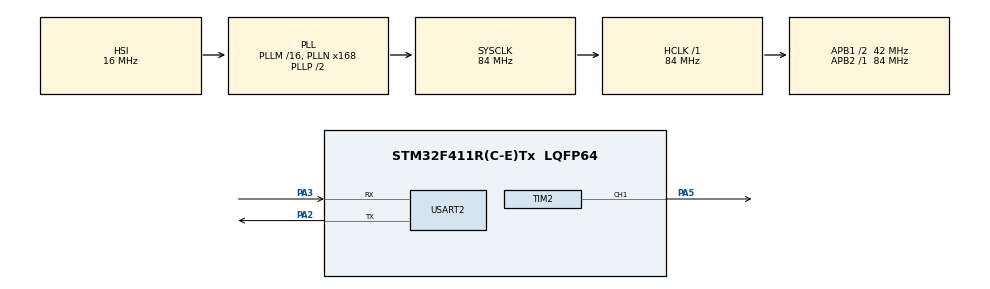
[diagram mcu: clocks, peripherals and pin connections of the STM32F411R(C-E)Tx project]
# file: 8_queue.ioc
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Dma.MEMTOMEM.0.Direction=DMA_MEMORY_TO_MEMORY
Dma.MEMTOMEM.0.FIFOMode=DMA_FIFOMODE_ENABLE
Dma.MEMTOMEM.0.FIFOThreshold=DMA_FIFO_THRESHOLD_FULL
Dma.MEMTOMEM.0.Instance=DMA2_Stream0
Dma.MEMTOMEM.0.MemBurst=DMA_MBURST_SINGLE
Dma.MEMTOMEM.0.MemDataAlignment=DMA_MDATAALIGN_BYTE
Dma.MEMTOMEM.0.MemInc=DMA_MINC_ENABLE
Dma.MEMTOMEM.0.Mode=DMA_NORMAL
Dma.MEMTOMEM.0.PeriphBurst=DMA_PBURST_SINGLE
Dma.MEMTOMEM.0.PeriphDataAlignment=DMA_PDATAALIGN_BYTE
Dma.MEMTOMEM.0.PeriphInc=DMA_PINC_ENABLE
Dma.MEMTOMEM.0.Priority=DMA_PRIORITY_LOW
Dma.Request0=MEMTOMEM
Mcu.Family=STM32F4
Mcu.Name=STM32F411R(C-E)Tx
Mcu.Package=LQFP64
NVIC.PriorityGroup=NVIC_PRIORITYGROUP_4
NVIC.TIM5_IRQn=true\:15\:0\:false\:false\:true\:false\:true\:true
NVIC.TimeBase=TIM5_IRQn
NVIC.TimeBaseIP=TIM5
NVIC.USART2_IRQn=true\:6\:0\:true\:false\:true\:true\:true\:true
PA13.Mode=Serial_Wire
PA13.Signal=SYS_JTMS-SWDIO
PA14.Mode=Serial_Wire
PA14.Signal=SYS_JTCK-SWCLK
PA2.Mode=Asynchronous
PA2.Signal=USART2_TX
PA3.Mode=Asynchronous
PA3.Signal=USART2_RX
PA5.Signal=S_TIM2_CH1_ETR
ProjectManager.HeapSize=0x200
ProjectManager.StackSize=0x400
ProjectManager.TargetToolchain=STM32CubeIDE
RCC.48MHZClocksFreq_Value=42000000
RCC.AHBFreq_Value=84000000
RCC.APB1CLKDivider=RCC_HCLK_DIV2
RCC.APB1Freq_Value=42000000
RCC.APB1TimFreq_Value=84000000
RCC.APB2Freq_Value=84000000
RCC.APB2TimFreq_Value=84000000
RCC.CortexFreq_Value=84000000
RCC.HCLKFreq_Value=84000000
RCC.HSE_VALUE=25000000
RCC.HSI_VALUE=16000000
RCC.LSE_VALUE=32768
RCC.PLLN=168
RCC.SYSCLKFreq_VALUE=84000000
RCC.SYSCLKSource=RCC_SYSCLKSOURCE_PLLCLK
RCC.VCOOutputFreq_Value=168000000
SH.S_TIM2_CH1_ETR.0=TIM2_CH1,PWM Generation1 CH1
TIM2.Channel-PWM\ Generation1\ CH1=TIM_CHANNEL_1
TIM2.Period=999
TIM2.Prescaler=83
TIM2.Pulse-PWM\ Generation1\ CH1=31250
USART2.VirtualMode=VM_ASYNC
VP_RTC_VS_RTC_Activate.Mode=RTC_Enabled
VP_SYS_VS_tim5.Mode=TIM5
VP_TIM2_VS_ClockSourceINT.Mode=Internal
board=custom

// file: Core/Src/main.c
/* USER CODE BEGIN Header */
/**
 ******************************************************************************
 * @file           : main.c
 * @brief          : Main program body
 ******************************************************************************
 * @attention
 *
 * Copyright (c) 2024 STMicroelectronics.
 * All rights reserved.
 *
 * This software is licensed under terms that can be found in the LICENSE file
 * in the root directory of this software component.
 * If no LICENSE file comes with this software, it is provided AS-IS.
 *
 ******************************************************************************
 */
/* USER CODE END Header */
#include "main.h"

/* USER CODE BEGIN PD */
xTaskHandle handle_cmd_task;
xTaskHandle handle_menu_task;
xTaskHandle handle_uart_task;
xTaskHandle handle_led_task;
xTaskHandle handle_rtc_task;
xTaskHandle handle_dma_task;

TimerHandle_t handle_led_timer;

QueueHandle_t q_data;
QueueHandle_t q_print;

volatile uint8_t user_data;

/* USER CODE END PD */

RTC_HandleTypeDef hrtc;

TIM_HandleTypeDef htim2;

UART_HandleTypeDef huart2;

DMA_HandleTypeDef hdma_memtomem_dma2_stream0;
/* USER CODE BEGIN PV */
char hello[18] = "Hello, Project 8.\n";
/* USER CODE END PV */

void SystemClock_Config(void);
static void MX_GPIO_Init(void);
static void MX_DMA_Init(void);
static void MX_RTC_Init(void);
static void MX_USART2_UART_Init(void);
static void MX_TIM2_Init(void);
/* USER CODE BEGIN PFP */
void led_effect_callback(TimerHandle_t xTimer);
/* USER CODE END PFP */

int main(void) {

	/* USER CODE BEGIN 1 */
	BaseType_t status;
	/* USER CODE END 1 */

	/* MCU Configuration--------------------------------------------------------*/

	/* Reset of all peripherals, Initializes the Flash interface and the Systick. */
	HAL_Init();

	/* Configure the system clock */
	SystemClock_Config();

	/* Initialize all configured peripherals */
	MX_GPIO_Init();
	MX_DMA_Init();
	MX_RTC_Init();
	MX_USART2_UART_Init();
	MX_TIM2_Init();
	/* USER CODE BEGIN 2 */
	HAL_TIM_PWM_Start(&htim2, TIM_CHANNEL_1); /* Start PWM */

	status = xTaskCreate(menu_task, "menu_task", 250, NULL, 2,
			&handle_menu_task);
	configASSERT(status == pdPASS);

	status = xTaskCreate(uart_task, "uart_task", 250, NULL, 2,
			&handle_uart_task);
	configASSERT(status == pdPASS);

	status = xTaskCreate(cmd_handler_task, "cmd_task", 250, NULL, 2,
			&handle_cmd_task);
	configASSERT(status == pdPASS);

	status = xTaskCreate(led_task, "led_task", 250, NULL, 2, &handle_led_task);
	configASSERT(status == pdPASS);

	status = xTaskCreate(rtc_task, "rtc_task", 250, NULL, 2, &handle_rtc_task);
	configASSERT(status == pdPASS);

	status = xTaskCreate(dma_task, "dma_task", 250, NULL, 2, &handle_dma_task);
	configASSERT(status == pdPASS);

	q_data = xQueueCreate(10, sizeof(char));
	configASSERT(q_data != NULL);

	q_print = xQueueCreate(10, sizeof(size_t));
	configASSERT(q_print != NULL);

	//Create software timers for LED effects
	handle_led_timer = xTimerCreate("led_timer", pdMS_TO_TICKS(250),
	pdTRUE, (void*) 1, led_effect_callback);

	HAL_UART_Transmit(&huart2, (uint8_t*) hello, strlen(hello), 100);
	HAL_UART_Receive_IT(&huart2, (uint8_t*) &user_data, 1);

	vTaskStartScheduler();
	/* USER CODE END 2 */

	/* Infinite loop */
	while (1) {

	}
}

void SystemClock_Config(void) {
	RCC_OscInitTypeDef RCC_OscInitStruct = { 0 };
	RCC_ClkInitTypeDef RCC_ClkInitStruct = { 0 };

	/** Configure the main internal regulator output voltage
	 */
	__HAL_RCC_PWR_CLK_ENABLE();
	__HAL_PWR_VOLTAGESCALING_CONFIG(PWR_REGULATOR_VOLTAGE_SCALE1);

	/** Initializes the RCC Oscillators according to the specified parameters
	 * in the RCC_OscInitTypeDef structure.
	 */
	RCC_OscInitStruct.OscillatorType = RCC_OSCILLATORTYPE_HSI
			| RCC_OSCILLATORTYPE_LSI;
	RCC_OscInitStruct.HSIState = RCC_HSI_ON;
	RCC_OscInitStruct.HSICalibrationValue = RCC_HSICALIBRATION_DEFAULT;
	RCC_OscInitStruct.LSIState = RCC_LSI_ON;
	RCC_OscInitStruct.PLL.PLLState = RCC_PLL_ON;
	RCC_OscInitStruct.PLL.PLLSource = RCC_PLLSOURCE_HSI;
	RCC_OscInitStruct.PLL.PLLM = 16;
	RCC_OscInitStruct.PLL.PLLN = 168;
	RCC_OscInitStruct.PLL.PLLP = RCC_PLLP_DIV2;
	RCC_OscInitStruct.PLL.PLLQ = 4;
	if (HAL_RCC_OscConfig(&RCC_OscInitStruct) != HAL_OK) {
		Error_Handler();
	}

	/** Initializes the CPU, AHB and APB buses clocks
	 */
	RCC_ClkInitStruct.ClockType = RCC_CLOCKTYPE_HCLK | RCC_CLOCKTYPE_SYSCLK
			| RCC_CLOCKTYPE_PCLK1 | RCC_CLOCKTYPE_PCLK2;
	RCC_ClkInitStruct.SYSCLKSource = RCC_SYSCLKSOURCE_PLLCLK;
	RCC_ClkInitStruct.AHBCLKDivider = RCC_SYSCLK_DIV1;
	RCC_ClkInitStruct.APB1CLKDivider = RCC_HCLK_DIV2;
	RCC_ClkInitStruct.APB2CLKDivider = RCC_HCLK_DIV1;

	if (HAL_RCC_ClockConfig(&RCC_ClkInitStruct, FLASH_LATENCY_2) != HAL_OK) {
		Error_Handler();
	}
}

static void MX_RTC_Init(void) {

	/** Initialize RTC Only
	 */
	hrtc.Instance = RTC;
	hrtc.Init.HourFormat = RTC_HOURFORMAT_24;
	hrtc.Init.AsynchPrediv = 127;
	hrtc.Init.SynchPrediv = 255;
	hrtc.Init.OutPut = RTC_OUTPUT_DISABLE;
	hrtc.Init.OutPutPolarity = RTC_OUTPUT_POLARITY_HIGH;
	hrtc.Init.OutPutType = RTC_OUTPUT_TYPE_OPENDRAIN;
	if (HAL_RTC_Init(&hrtc) != HAL_OK) {
		Error_Handler();
	}

}

static void MX_TIM2_Init(void) {

	TIM_ClockConfigTypeDef sClockSourceConfig = { 0 };
	TIM_MasterConfigTypeDef sMasterConfig = { 0 };
	TIM_OC_InitTypeDef sConfigOC = { 0 };

	htim2.Instance = TIM2;
	htim2.Init.Prescaler = 83;
	htim2.Init.CounterMode = TIM_COUNTERMODE_UP;
	htim2.Init.Period = 999;
	htim2.Init.ClockDivision = TIM_CLOCKDIVISION_DIV1;
	htim2.Init.AutoReloadPreload = TIM_AUTORELOAD_PRELOAD_DISABLE;
	if (HAL_TIM_Base_Init(&htim2) != HAL_OK) {
		Error_Handler();
	}
	sClockSourceConfig.ClockSource = TIM_CLOCKSOURCE_INTERNAL;
	if (HAL_TIM_ConfigClockSource(&htim2, &sClockSourceConfig) != HAL_OK) {
		Error_Handler();
	}
	if (HAL_TIM_PWM_Init(&htim2) != HAL_OK) {
		Error_Handler();
	}
	sMasterConfig.MasterOutputTrigger = TIM_TRGO_RESET;
	sMasterConfig.MasterSlaveMode = TIM_MASTERSLAVEMODE_DISABLE;
	if (HAL_TIMEx_MasterConfigSynchronization(&htim2, &sMasterConfig)
			!= HAL_OK) {
		Error_Handler();
	}
	sConfigOC.OCMode = TIM_OCMODE_PWM1;
	sConfigOC.Pulse = 31250;
	sConfigOC.OCPolarity = TIM_OCPOLARITY_HIGH;
	sConfigOC.OCFastMode = TIM_OCFAST_DISABLE;
	if (HAL_TIM_PWM_ConfigChannel(&htim2, &sConfigOC, TIM_CHANNEL_1)
			!= HAL_OK) {
		Error_Handler();
	}
	HAL_TIM_MspPostInit(&htim2);

}

static void MX_USART2_UART_Init(void) {

	huart2.Instance = USART2;
	huart2.Init.BaudRate = 115200;
	huart2.Init.WordLength = UART_WORDLENGTH_8B;
	huart2.Init.StopBits = UART_STOPBITS_1;
	huart2.Init.Parity = UART_PARITY_NONE;
	huart2.Init.Mode = UART_MODE_TX_RX;
	huart2.Init.HwFlowCtl = UART_HWCONTROL_NONE;
	huart2.Init.OverSampling = UART_OVERSAMPLING_16;
	if (HAL_UART_Init(&huart2) != HAL_OK) {
		Error_Handler();
	}

}

static void MX_DMA_Init(void) {

	/* DMA controller clock enable */
	__HAL_RCC_DMA2_CLK_ENABLE();

	/* Configure DMA request hdma_memtomem_dma2_stream0 on DMA2_Stream0 */
	hdma_memtomem_dma2_stream0.Instance = DMA2_Stream0;
	hdma_memtomem_dma2_stream0.Init.Channel = DMA_CHANNEL_0;
	hdma_memtomem_dma2_stream0.Init.Direction = DMA_MEMORY_TO_MEMORY;
	hdma_memtomem_dma2_stream0.Init.PeriphInc = DMA_PINC_ENABLE;
	hdma_memtomem_dma2_stream0.Init.MemInc = DMA_MINC_ENABLE;
	hdma_memtomem_dma2_stream0.Init.PeriphDataAlignment = DMA_PDATAALIGN_BYTE;
	hdma_memtomem_dma2_stream0.Init.MemDataAlignment = DMA_MDATAALIGN_BYTE;
	hdma_memtomem_dma2_stream0.Init.Mode = DMA_NORMAL;
	hdma_memtomem_dma2_stream0.Init.Priority = DMA_PRIORITY_LOW;
	hdma_memtomem_dma2_stream0.Init.FIFOMode = DMA_FIFOMODE_ENABLE;
	hdma_memtomem_dma2_stream0.Init.FIFOThreshold = DMA_FIFO_THRESHOLD_FULL;
	hdma_memtomem_dma2_stream0.Init.MemBurst = DMA_MBURST_SINGLE;
	hdma_memtomem_dma2_stream0.Init.PeriphBurst = DMA_PBURST_SINGLE;
	if (HAL_DMA_Init(&hdma_memtomem_dma2_stream0) != HAL_OK) {
		Error_Handler();
	}

}

static void MX_GPIO_Init(void) {

	/* GPIO Ports Clock Enable */
	__HAL_RCC_GPIOA_CLK_ENABLE();

}

/* USER CODE BEGIN 4 */

/* This function called from UART interrupt handler , hence executes in interrupt context */
void HAL_UART_RxCpltCallback(UART_HandleTypeDef *huart) {
	uint8_t dummy;

	for (uint32_t i = 0; i < 150; i++)
		;

	HAL_UART_Transmit_IT(&huart2, (uint8_t*) &user_data, 1);

	if (!xQueueIsQueueFullFromISR(q_data)) {
		/*Enqueue data byte */
		xQueueSendFromISR(q_data, (void* )&user_data, NULL);
	} else {
		if (user_data == '\n') {
			/*Make sure that last data byte of the queue is '\n' */
			xQueueReceiveFromISR(q_data, (void*) &dummy, NULL); // task out an element from queue
			xQueueSendFromISR(q_data, (void* )&user_data, NULL); // then push the element into the queue
		}
	}

	/*Send notification to command handling task if user_data = '\n' */
	if (user_data == '\n') {
		/*send notification to command handling task */
		xTaskNotifyFromISR(handle_cmd_task, 0, eNoAction, NULL);
	}

	/* Enable UART data byte reception again in IT mode */
	HAL_UART_Receive_IT(&huart2, (uint8_t*) &user_data, 1);
}

void led_effect_callback(TimerHandle_t xTimer) {
	static uint32_t brightness = 0;
	static int8_t direction = 1;

	for (int i = 0; i < 1000; i++) {
		brightness += direction;
		__HAL_TIM_SET_COMPARE(&htim2, TIM_CHANNEL_1, brightness);
		HAL_Delay(1);
	}

	direction = 0 - direction;

//	HAL_GPIO_TogglePin(GPIOA, GPIO_PIN_5);
}

/* USER CODE END 4 */

void HAL_TIM_PeriodElapsedCallback(TIM_HandleTypeDef *htim) {
	if (htim->Instance == TIM5) {
		HAL_IncTick();
	}
}

void Error_Handler(void) {
	__disable_irq();
	while (1) {
	}
}
